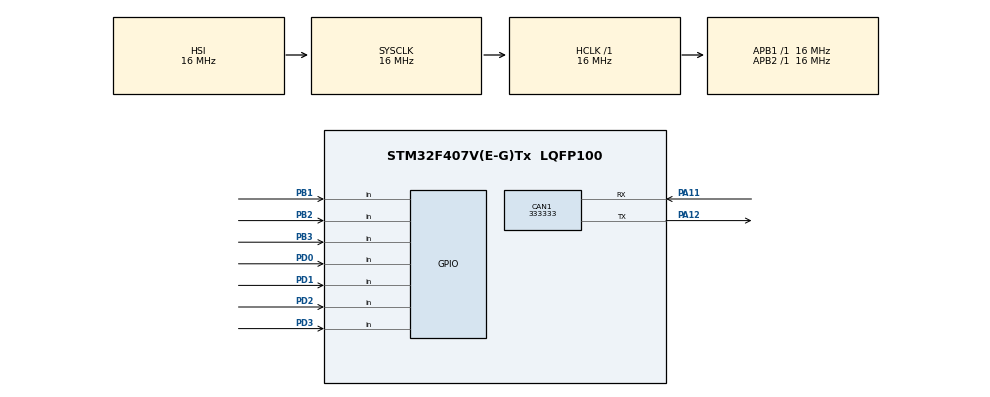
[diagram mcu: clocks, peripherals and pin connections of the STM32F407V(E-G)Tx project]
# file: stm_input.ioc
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CAN1.CalculateBaudRate=333333
CAN1.CalculateTimeBit=3000
CAN1.CalculateTimeQuantum=1000.0
Mcu.Family=STM32F4
Mcu.Name=STM32F407V(E-G)Tx
Mcu.Package=LQFP100
NVIC.PriorityGroup=NVIC_PRIORITYGROUP_4
PA11.Mode=CAN_Activate
PA11.Signal=CAN1_RX
PA12.Mode=CAN_Activate
PA12.Signal=CAN1_TX
PA13.Mode=Serial_Wire
PA13.Signal=SYS_JTMS-SWDIO
PA14.Mode=Serial_Wire
PA14.Signal=SYS_JTCK-SWCLK
PB1.Signal=GPIO_Input
PB2.Signal=GPIO_Input
PB3.Signal=GPIO_Input
PD0.Signal=GPIO_Input
PD1.Signal=GPIO_Input
PD2.Signal=GPIO_Input
PD3.Signal=GPIO_Input
PH0-OSC_IN.Mode=HSE-External-Oscillator
PH0-OSC_IN.Signal=RCC_OSC_IN
PH1-OSC_OUT.Mode=HSE-External-Oscillator
PH1-OSC_OUT.Signal=RCC_OSC_OUT
ProjectManager.HeapSize=0x200
ProjectManager.StackSize=0x400
ProjectManager.TargetToolchain=STM32CubeIDE
RCC.AHBFreq_Value=16000000
RCC.APB1Freq_Value=16000000
RCC.APB2Freq_Value=16000000
RCC.CortexFreq_Value=16000000
RCC.HSE_VALUE=25000000
RCC.HSI_VALUE=16000000
RCC.LSE_VALUE=32768
RCC.SYSCLKFreq_VALUE=16000000
RCC.VCOOutputFreq_Value=192000000
board=custom

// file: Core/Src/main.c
/* USER CODE BEGIN Header */
/**
  ******************************************************************************
  * @file           : main.c
  * @brief          : Main program body
  ******************************************************************************
  * @attention
  *
  * Copyright (c) 2023 STMicroelectronics.
  * All rights reserved.
  *
  * This software is licensed under terms that can be found in the LICENSE file
  * in the root directory of this software component.
  * If no LICENSE file comes with this software, it is provided AS-IS.
  *
  ******************************************************************************
  */
/* USER CODE END Header */
#include "main.h"
#include <stdio.h>
#include "stm32f4xx.h"
#include <string.h>

CAN_HandleTypeDef hcan1;

void SystemClock_Config(void);
static void MX_GPIO_Init(void);
static void MX_CAN1_Init(void);

int main(void)
{
  /* USER CODE BEGIN 1 */
char gearCombination[10];

  /* USER CODE END 1 */

  /* MCU Configuration--------------------------------------------------------*/

  /* Reset of all peripherals, Initializes the Flash interface and the Systick. */
  HAL_Init();

  /* Configure the system clock */
  SystemClock_Config();

  /* Initialize all configured peripherals */
  MX_GPIO_Init();
  MX_CAN1_Init();

  /* Infinite loop */
  while (1)
  {
	  GPIO_PinState rotarySwitchState0 = HAL_GPIO_ReadPin(GPIOD, GPIO_PIN_0);
	  GPIO_PinState rotarySwitchState1 = HAL_GPIO_ReadPin(GPIOD, GPIO_PIN_1);
	  GPIO_PinState rotarySwitchState2 = HAL_GPIO_ReadPin(GPIOD, GPIO_PIN_2);
	  GPIO_PinState rotarySwitchState3 = HAL_GPIO_ReadPin(GPIOD, GPIO_PIN_3);

	  GPIO_PinState limitSwitchState1 = HAL_GPIO_ReadPin(GPIOB, GPIO_PIN_1);
	  GPIO_PinState limitSwitchState2 = HAL_GPIO_ReadPin(GPIOB, GPIO_PIN_2);
	  GPIO_PinState limitSwitchState3 = HAL_GPIO_ReadPin(GPIOB, GPIO_PIN_4);

	  if (rotarySwitchState0 == GPIO_PIN_SET){
		  strcpy(gearCombination, "LR");
	  }
	  else if (rotarySwitchState1 == GPIO_PIN_SET){
		  strcpy(gearCombination, "N");
	  }
	  else if (rotarySwitchState2 == GPIO_PIN_SET){
	      gearCombination[0] = "L";
	  }
	  else if (rotarySwitchState3 == GPIO_PIN_SET){
	      gearCombination[0] = "H";
	  }
	  else {
	      printf("Error in Rotary switch");
	  }

	  if (gearCombination[0]=="L"|| gearCombination[0]=="H")
	  {
	      if (limitSwitchState1 == GPIO_PIN_SET){
	      gearCombination[1] = "1";
	      }
	  else if (limitSwitchState2 == GPIO_PIN_SET){
	      gearCombination[1] = "2";
	  	  }
	  else if (rotarySwitchState3 == GPIO_PIN_SET){
	      gearCombination[1] = "3";
	  	  }
	  }

  }
}

void SystemClock_Config(void)
{
  RCC_OscInitTypeDef RCC_OscInitStruct = {0};
  RCC_ClkInitTypeDef RCC_ClkInitStruct = {0};

  /** Configure the main internal regulator output voltage
  */
  __HAL_RCC_PWR_CLK_ENABLE();
  __HAL_PWR_VOLTAGESCALING_CONFIG(PWR_REGULATOR_VOLTAGE_SCALE1);

  /** Initializes the RCC Oscillators according to the specified parameters
  * in the RCC_OscInitTypeDef structure.
  */
  RCC_OscInitStruct.OscillatorType = RCC_OSCILLATORTYPE_HSI;
  RCC_OscInitStruct.HSIState = RCC_HSI_ON;
  RCC_OscInitStruct.HSICalibrationValue = RCC_HSICALIBRATION_DEFAULT;
  RCC_OscInitStruct.PLL.PLLState = RCC_PLL_NONE;
  if (HAL_RCC_OscConfig(&RCC_OscInitStruct) != HAL_OK)
  {
    Error_Handler();
  }

  /** Initializes the CPU, AHB and APB buses clocks
  */
  RCC_ClkInitStruct.ClockType = RCC_CLOCKTYPE_HCLK|RCC_CLOCKTYPE_SYSCLK
                              |RCC_CLOCKTYPE_PCLK1|RCC_CLOCKTYPE_PCLK2;
  RCC_ClkInitStruct.SYSCLKSource = RCC_SYSCLKSOURCE_HSI;
  RCC_ClkInitStruct.AHBCLKDivider = RCC_SYSCLK_DIV1;
  RCC_ClkInitStruct.APB1CLKDivider = RCC_HCLK_DIV1;
  RCC_ClkInitStruct.APB2CLKDivider = RCC_HCLK_DIV1;

  if (HAL_RCC_ClockConfig(&RCC_ClkInitStruct, FLASH_LATENCY_0) != HAL_OK)
  {
    Error_Handler();
  }
}

static void MX_CAN1_Init(void)
{

  hcan1.Instance = CAN1;
  hcan1.Init.Prescaler = 16;
  hcan1.Init.Mode = CAN_MODE_NORMAL;
  hcan1.Init.SyncJumpWidth = CAN_SJW_1TQ;
  hcan1.Init.TimeSeg1 = CAN_BS1_1TQ;
  hcan1.Init.TimeSeg2 = CAN_BS2_1TQ;
  hcan1.Init.TimeTriggeredMode = DISABLE;
  hcan1.Init.AutoBusOff = DISABLE;
  hcan1.Init.AutoWakeUp = DISABLE;
  hcan1.Init.AutoRetransmission = DISABLE;
  hcan1.Init.ReceiveFifoLocked = DISABLE;
  hcan1.Init.TransmitFifoPriority = DISABLE;
  if (HAL_CAN_Init(&hcan1) != HAL_OK)
  {
    Error_Handler();
  }

}

static void MX_GPIO_Init(void)
{
  GPIO_InitTypeDef GPIO_InitStruct = {0};

  /* GPIO Ports Clock Enable */
  __HAL_RCC_GPIOH_CLK_ENABLE();
  __HAL_RCC_GPIOB_CLK_ENABLE();
  __HAL_RCC_GPIOA_CLK_ENABLE();
  __HAL_RCC_GPIOD_CLK_ENABLE();

  /*Configure GPIO pins : PB1 PB2 PB3 */
  GPIO_InitStruct.Pin = GPIO_PIN_1|GPIO_PIN_2|GPIO_PIN_3;
  GPIO_InitStruct.Mode = GPIO_MODE_INPUT;
  GPIO_InitStruct.Pull = GPIO_NOPULL;
  HAL_GPIO_Init(GPIOB, &GPIO_InitStruct);

  /*Configure GPIO pins : PD0 PD1 PD2 PD3 */
  GPIO_InitStruct.Pin = GPIO_PIN_0|GPIO_PIN_1|GPIO_PIN_2|GPIO_PIN_3;
  GPIO_InitStruct.Mode = GPIO_MODE_INPUT;
  GPIO_InitStruct.Pull = GPIO_NOPULL;
  HAL_GPIO_Init(GPIOD, &GPIO_InitStruct);

}

void Error_Handler(void)
{
  __disable_irq();
  while (1)
  {
  }
}
